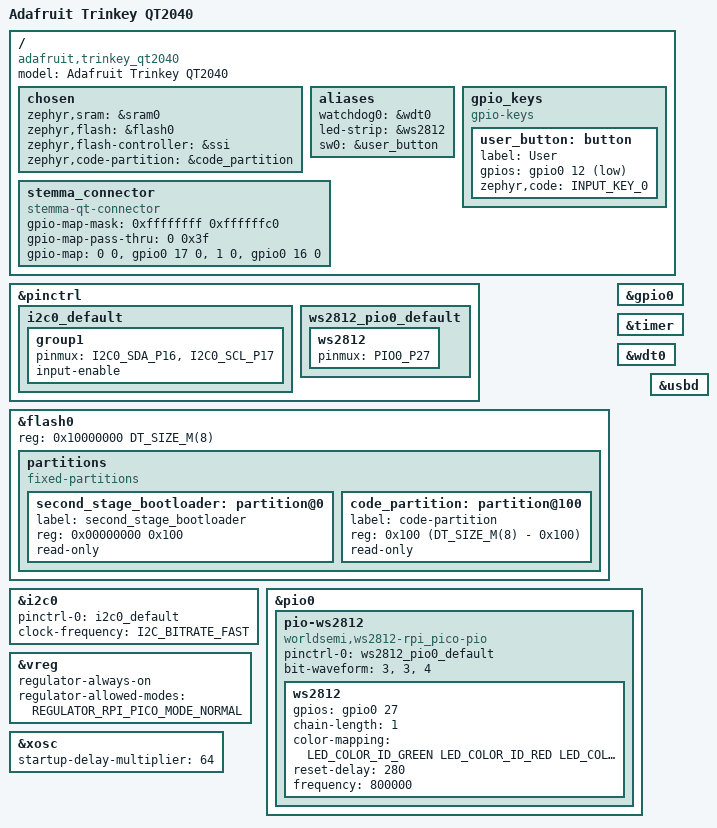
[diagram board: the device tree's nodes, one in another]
/*
 * Copyright (c) 2021 Yonatan Schachter
 * Copyright (c) 2022 Peter Johanson
 * Copyright (c) 2025 Jonas Berg
 *
 * SPDX-License-Identifier: Apache-2.0
 */

/dts-v1/;

#include <raspberrypi/rpi_pico/rp2040.dtsi>
#include <dt-bindings/pinctrl/rpi-pico-rp2040-pinctrl.h>
#include <zephyr/dt-bindings/input/input-event-codes.h>
#include <zephyr/dt-bindings/led/led.h>

/ {
	model = "Adafruit Trinkey QT2040";
	compatible = "adafruit,trinkey_qt2040";

	chosen {
		zephyr,sram = &sram0;
		zephyr,flash = &flash0;
		zephyr,flash-controller = &ssi;
		zephyr,code-partition = &code_partition;
	};

	aliases {
		watchdog0 = &wdt0;
		led-strip = &ws2812;
		sw0 = &user_button;
	};

	gpio_keys {
		compatible = "gpio-keys";

		user_button: button {
			label = "User";
			gpios = <&gpio0 12 (GPIO_ACTIVE_LOW | GPIO_PULL_UP)>;
			zephyr,code = <INPUT_KEY_0>;
		};
	};

	stemma_connector: stemma_connector {
		compatible = "stemma-qt-connector";
		#gpio-cells = <2>;
		gpio-map-mask = <0xffffffff 0xffffffc0>;
		gpio-map-pass-thru = <0 0x3f>;
		gpio-map = <0 0 &gpio0 17 0>,
			<1 0 &gpio0 16 0>;
	};
};

&pinctrl {
	i2c0_default: i2c0_default {
		group1 {
			pinmux = <I2C0_SDA_P16>, <I2C0_SCL_P17>;
			input-enable;
		};
	};

	ws2812_pio0_default: ws2812_pio0_default {
		ws2812 {
			pinmux = <PIO0_P27>;
		};
	};
};

&flash0 {
	reg = <0x10000000 DT_SIZE_M(8)>;

	partitions {
		compatible = "fixed-partitions";
		#address-cells = <1>;
		#size-cells = <1>;

		/* Reserved memory for the second stage bootloader */
		second_stage_bootloader: partition@0 {
			label = "second_stage_bootloader";
			reg = <0x00000000 0x100>;
			read-only;
		};

		/*
		 * Usable flash. Starts at 0x100, after the bootloader. The partition
		 * size is 8 MB minus the 0x100 bytes taken by the bootloader.
		 */
		code_partition: partition@100 {
			label = "code-partition";
			reg = <0x100 (DT_SIZE_M(8) - 0x100)>;
			read-only;
		};
	};
};

&gpio0 {
	status = "okay";
};

zephyr_i2c: &i2c0 {
	status = "okay";
	pinctrl-0 = <&i2c0_default>;
	pinctrl-names = "default";
	clock-frequency = <I2C_BITRATE_FAST>;
};

&timer {
	status = "okay";
};

&wdt0 {
	status = "okay";
};

&pio0 {
	status = "okay";

	pio-ws2812 {
		compatible = "worldsemi,ws2812-rpi_pico-pio";
		status = "okay";
		pinctrl-0 = <&ws2812_pio0_default>;
		pinctrl-names = "default";
		bit-waveform = <3>, <3>, <4>;

		ws2812: ws2812 {
			status = "okay";
			gpios = <&gpio0 27 GPIO_ACTIVE_HIGH>;
			chain-length = <1>;
			color-mapping = <LED_COLOR_ID_GREEN
				LED_COLOR_ID_RED
				LED_COLOR_ID_BLUE>;
			reset-delay = <280>;
			frequency = <800000>;
		};
	};
};

zephyr_udc0: &usbd {
	status = "okay";
};

&vreg {
	regulator-always-on;
	regulator-allowed-modes = <REGULATOR_RPI_PICO_MODE_NORMAL>;
};

&xosc {
	startup-delay-multiplier = <64>;
};

#include <../boards/common/usb/cdc_acm_serial.dtsi>
